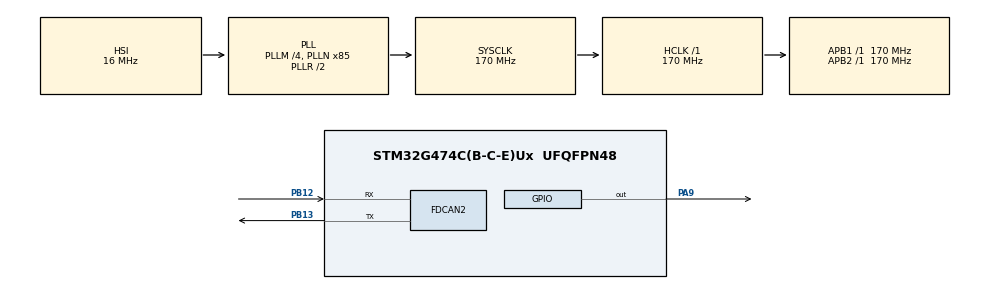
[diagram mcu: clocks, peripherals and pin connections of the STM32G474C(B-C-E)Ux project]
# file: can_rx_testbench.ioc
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FDCAN2.CalculateBaudRateNominal=3541666
FDCAN2.CalculateTimeBitNominal=282
FDCAN2.CalculateTimeQuantumNominal=94.11764705882354
Mcu.Family=STM32G4
Mcu.Name=STM32G474C(B-C-E)Ux
Mcu.Package=UFQFPN48
NVIC.FDCAN2_IT0_IRQn=true\:0\:0\:false\:false\:true\:true\:true\:true
NVIC.PriorityGroup=NVIC_PRIORITYGROUP_4
PA9.Signal=GPIO_Output
PB12.Mode=FDCAN_Activate
PB12.Signal=FDCAN2_RX
PB13.Mode=FDCAN_Activate
PB13.Signal=FDCAN2_TX
ProjectManager.HeapSize=0x200
ProjectManager.StackSize=0x400
ProjectManager.TargetToolchain=CMake
RCC.ADC12Freq_Value=170000000
RCC.ADC345Freq_Value=170000000
RCC.AHBFreq_Value=170000000
RCC.APB1Freq_Value=170000000
RCC.APB1TimFreq_Value=170000000
RCC.APB2Freq_Value=170000000
RCC.APB2TimFreq_Value=170000000
RCC.CortexFreq_Value=170000000
RCC.EXTERNAL_CLOCK_VALUE=12288000
RCC.HCLKFreq_Value=170000000
RCC.HSE_VALUE=8000000
RCC.HSI48_VALUE=48000000
RCC.HSI_VALUE=16000000
RCC.LSE_VALUE=32768
RCC.PLLM=RCC_PLLM_DIV4
RCC.PLLN=85
RCC.SYSCLKFreq_VALUE=170000000
RCC.SYSCLKSource=RCC_SYSCLKSOURCE_PLLCLK
RCC.USBFreq_Value=170000000
RCC.VCOOutputFreq_Value=340000000
VP_SYS_VS_DBSignals.Mode=DisableDeadBatterySignals
board=custom

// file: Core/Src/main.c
/* USER CODE BEGIN Header */
/**
  ******************************************************************************
  * @file           : main.c
  * @brief          : Main program body
  ******************************************************************************
  * @attention
  *
  * Copyright (c) 2026 STMicroelectronics.
  * All rights reserved.
  *
  * This software is licensed under terms that can be found in the LICENSE file
  * in the root directory of this software component.
  * If no LICENSE file comes with this software, it is provided AS-IS.
  *
  ******************************************************************************
  */
/* USER CODE END Header */
#include "main.h"
#include "stm32g4xx_hal_gpio.h"

FDCAN_HandleTypeDef hfdcan2;

/* USER CODE BEGIN PV */
FDCAN_RxHeaderTypeDef RxHeader;
uint8_t RxData[8];
/* USER CODE END PV */

void SystemClock_Config(void);
static void MX_GPIO_Init(void);
static void MX_FDCAN2_Init(void);

int main(void)
{

  /* MCU Configuration--------------------------------------------------------*/

  /* Reset of all peripherals, Initializes the Flash interface and the Systick. */
  HAL_Init();

  /* USER CODE BEGIN Init */
  hfdcan2.Init.StdFiltersNbr = 0;
  hfdcan2.Init.ExtFiltersNbr = 0;
  /* USER CODE END Init */

  /* Configure the system clock */
  SystemClock_Config();

  /* Initialize all configured peripherals */
  MX_GPIO_Init();
  MX_FDCAN2_Init();
  /* USER CODE BEGIN 2 */
  if (HAL_FDCAN_ConfigGlobalFilter(&hfdcan2,
                                  FDCAN_ACCEPT_IN_RX_FIFO0,  // Non-matching standard IDs
                                  FDCAN_ACCEPT_IN_RX_FIFO0,  // Non-matching extended IDs
                                  FDCAN_REJECT_REMOTE,       // Reject standard remote frames
                                  FDCAN_REJECT_REMOTE) != HAL_OK)
  {
    Error_Handler();
  }

  /* Activate RX FIFO 0 new message notification */
  if (HAL_FDCAN_ActivateNotification(&hfdcan2,
                                    FDCAN_IT_RX_FIFO0_NEW_MESSAGE,
                                    0) != HAL_OK)
  {
    Error_Handler();
  }

  /* Start FDCAN */
  if (HAL_FDCAN_Start(&hfdcan2) != HAL_OK)
  {
    Error_Handler();
  }
  /* USER CODE END 2 */

  /* Infinite loop */
  while (1)
  {

  }
}

void SystemClock_Config(void)
{
  RCC_OscInitTypeDef RCC_OscInitStruct = {0};
  RCC_ClkInitTypeDef RCC_ClkInitStruct = {0};

  /** Configure the main internal regulator output voltage
  */
  HAL_PWREx_ControlVoltageScaling(PWR_REGULATOR_VOLTAGE_SCALE1_BOOST);

  /** Initializes the RCC Oscillators according to the specified parameters
  * in the RCC_OscInitTypeDef structure.
  */
  RCC_OscInitStruct.OscillatorType = RCC_OSCILLATORTYPE_HSI;
  RCC_OscInitStruct.HSIState = RCC_HSI_ON;
  RCC_OscInitStruct.HSICalibrationValue = RCC_HSICALIBRATION_DEFAULT;
  RCC_OscInitStruct.PLL.PLLState = RCC_PLL_ON;
  RCC_OscInitStruct.PLL.PLLSource = RCC_PLLSOURCE_HSI;
  RCC_OscInitStruct.PLL.PLLM = RCC_PLLM_DIV4;
  RCC_OscInitStruct.PLL.PLLN = 85;
  RCC_OscInitStruct.PLL.PLLP = RCC_PLLP_DIV2;
  RCC_OscInitStruct.PLL.PLLQ = RCC_PLLQ_DIV2;
  RCC_OscInitStruct.PLL.PLLR = RCC_PLLR_DIV2;
  if (HAL_RCC_OscConfig(&RCC_OscInitStruct) != HAL_OK)
  {
    Error_Handler();
  }

  /** Initializes the CPU, AHB and APB buses clocks
  */
  RCC_ClkInitStruct.ClockType = RCC_CLOCKTYPE_HCLK|RCC_CLOCKTYPE_SYSCLK
                              |RCC_CLOCKTYPE_PCLK1|RCC_CLOCKTYPE_PCLK2;
  RCC_ClkInitStruct.SYSCLKSource = RCC_SYSCLKSOURCE_PLLCLK;
  RCC_ClkInitStruct.AHBCLKDivider = RCC_SYSCLK_DIV1;
  RCC_ClkInitStruct.APB1CLKDivider = RCC_HCLK_DIV1;
  RCC_ClkInitStruct.APB2CLKDivider = RCC_HCLK_DIV1;

  if (HAL_RCC_ClockConfig(&RCC_ClkInitStruct, FLASH_LATENCY_4) != HAL_OK)
  {
    Error_Handler();
  }
}

static void MX_FDCAN2_Init(void)
{

  hfdcan2.Instance = FDCAN2;
  hfdcan2.Init.ClockDivider = FDCAN_CLOCK_DIV1;
  hfdcan2.Init.FrameFormat = FDCAN_FRAME_CLASSIC;
  hfdcan2.Init.Mode = FDCAN_MODE_NORMAL;
  hfdcan2.Init.AutoRetransmission = DISABLE;
  hfdcan2.Init.TransmitPause = DISABLE;
  hfdcan2.Init.ProtocolException = DISABLE;
  hfdcan2.Init.NominalPrescaler = 16;
  hfdcan2.Init.NominalSyncJumpWidth = 1;
  hfdcan2.Init.NominalTimeSeg1 = 1;
  hfdcan2.Init.NominalTimeSeg2 = 1;
  hfdcan2.Init.DataPrescaler = 1;
  hfdcan2.Init.DataSyncJumpWidth = 1;
  hfdcan2.Init.DataTimeSeg1 = 1;
  hfdcan2.Init.DataTimeSeg2 = 1;
  hfdcan2.Init.StdFiltersNbr = 0;
  hfdcan2.Init.ExtFiltersNbr = 0;
  hfdcan2.Init.TxFifoQueueMode = FDCAN_TX_FIFO_OPERATION;
  if (HAL_FDCAN_Init(&hfdcan2) != HAL_OK)
  {
    Error_Handler();
  }

}

static void MX_GPIO_Init(void)
{
  GPIO_InitTypeDef GPIO_InitStruct = {0};

  /* GPIO Ports Clock Enable */
  __HAL_RCC_GPIOB_CLK_ENABLE();
  __HAL_RCC_GPIOA_CLK_ENABLE();

  /*Configure GPIO pin Output Level */
  HAL_GPIO_WritePin(GPIOA, GPIO_PIN_9, GPIO_PIN_RESET);

  /*Configure GPIO pin : PA9 */
  GPIO_InitStruct.Pin = GPIO_PIN_9;
  GPIO_InitStruct.Mode = GPIO_MODE_OUTPUT_PP;
  GPIO_InitStruct.Pull = GPIO_NOPULL;
  GPIO_InitStruct.Speed = GPIO_SPEED_FREQ_LOW;
  HAL_GPIO_Init(GPIOA, &GPIO_InitStruct);

}

/* USER CODE BEGIN 4 */
/**
  * @brief FDCAN RX FIFO 0 callback
  * @param hfdcan FDCAN handle
  * @param RxFifo0ITs Interrupt flags
  */
void HAL_FDCAN_RxFifo0Callback(FDCAN_HandleTypeDef *hfdcan,
                                uint32_t RxFifo0ITs)
{
  if (hfdcan->Instance == FDCAN2)
  {
    if ((RxFifo0ITs & FDCAN_IT_RX_FIFO0_NEW_MESSAGE) != 0)
    {
      /* Read the message from RX FIFO 0 */
      if (HAL_FDCAN_GetRxMessage(hfdcan,
                                 FDCAN_RX_FIFO0,
                                 &RxHeader,
                                 RxData) == HAL_OK)
      {
        /*
         * Check for exactly 8 data bytes:
         * 0, 1, 2, 3, 4, 5, 6, 7
         */
        if ((RxHeader.DataLength == FDCAN_DLC_BYTES_8) &&
            (RxData[0] == 0) &&
            (RxData[1] == 1) &&
            (RxData[2] == 2) &&
            (RxData[3] == 3) &&
            (RxData[4] == 4) &&
            (RxData[5] == 5) &&
            (RxData[6] == 6) &&
            (RxData[7] == 7))
        {
          /*
           * Matching CAN message received.
           *
           * Turn on PA9 as an example response.
           */
          HAL_GPIO_WritePin(GPIOA, GPIO_PIN_9, GPIO_PIN_SET);
        }
      }
    }
  }
}
/* USER CODE END 4 */

void Error_Handler(void)
{
  __disable_irq();
  while (1)
  {
  }
}
